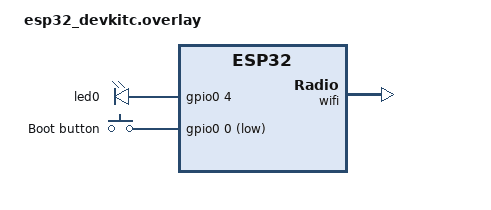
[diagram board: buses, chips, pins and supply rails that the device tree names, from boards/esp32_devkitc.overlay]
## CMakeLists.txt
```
cmake_minimum_required(VERSION 3.20.0)

find_package(Zephyr REQUIRED HINTS $ENV{ZEPHYR_BASE})
project(solution_http)

file(GLOB_RECURSE app_sources CONFIGURE_DEPENDS src/*.c)
target_sources(app PRIVATE ${app_sources})

set(gen_dir ${CMAKE_CURRENT_BINARY_DIR}/include/generated)
target_include_directories(app PRIVATE
    ${gen_dir}
    src
)

generate_inc_file_for_target(
    app
    web/index.html
    ${gen_dir}/index.html.inc
)

generate_inc_file_for_target(
    app
    web/style.css
    ${gen_dir}/style.css.inc
)

generate_inc_file_for_target(
    app
    web/app.js
    ${gen_dir}/app.js.inc
)

zephyr_linker_sources(SECTIONS src/web/sections-rom.ld)

zephyr_linker_section(
    NAME http_resource_desc_tv_scheduler
    KVMA RAM_REGION
    GROUP RODATA_REGION
)
```

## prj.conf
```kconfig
CONFIG_CRC=y
CONFIG_DNS_RESOLVER=y
CONFIG_EARLY_CONSOLE=y
CONFIG_EVENTFD=y
CONFIG_FLASH_MAP=y
CONFIG_FLASH=y
CONFIG_GPIO=y
CONFIG_HTTP_PARSER_URL=y
CONFIG_HTTP_PARSER=y
CONFIG_HTTP_SERVER_MAX_CLIENTS=10
CONFIG_HTTP_SERVER_RESOURCE_WILDCARD=y
CONFIG_HTTP_SERVER_STACK_SIZE=4096
CONFIG_HTTP_SERVER=y
CONFIG_IMG_MANAGER=y
CONFIG_INIT_STACKS=y
CONFIG_JSON_LIBRARY=y
CONFIG_LOG_BUFFER_SIZE=4096
CONFIG_LOG_MODE_DEFERRED=y
CONFIG_LOG=y
CONFIG_MCUMGR=y
CONFIG_NET_BUF_RX_COUNT=20
CONFIG_NET_BUF_RX_COUNT=32
CONFIG_NET_BUF_TX_COUNT=20
CONFIG_NET_BUF_TX_COUNT=32
CONFIG_NET_BUF=y
CONFIG_NET_CONFIG_AUTO_INIT=n
CONFIG_NET_CONNECTION_MANAGER=y
CONFIG_NET_DHCPV4_SERVER_LOG_LEVEL_DBG=y
CONFIG_NET_DHCPV4_SERVER=y
CONFIG_NET_DHCPV4=y
CONFIG_NET_IF_MAX_IPV4_COUNT=2
CONFIG_NET_IF_MAX_IPV6_COUNT=2
CONFIG_NET_IPV4=y
CONFIG_NET_IPV6=n
CONFIG_NET_L2_ETHERNET=y
CONFIG_NET_L2_WIFI_MGMT=y
CONFIG_NET_LOG=y
CONFIG_NET_MAX_CONN=16
CONFIG_NET_MAX_CONTEXTS=10
CONFIG_NET_MAX_CONTEXTS=16
CONFIG_NET_MAX_CONTEXTS=8
CONFIG_NET_MGMT_EVENT_INFO=y
CONFIG_NET_MGMT_EVENT_QUEUE_SIZE=10
CONFIG_NET_MGMT_EVENT_QUEUE_SIZE=16
CONFIG_NET_MGMT_EVENT_QUEUE_TIMEOUT=5000
CONFIG_NET_MGMT_EVENT_STACK_SIZE=4096
CONFIG_NET_MGMT_EVENT=y
CONFIG_NET_MGMT=y
CONFIG_NET_PKT_RX_COUNT=10
CONFIG_NET_PKT_RX_COUNT=16
CONFIG_NET_PKT_TX_COUNT=10
CONFIG_NET_PKT_TX_COUNT=16
CONFIG_NET_SOCKETS_SERVICE_STACK_SIZE=4096
CONFIG_NET_SOCKETS=y
CONFIG_NET_STATISTICS_PERIODIC_OUTPUT=n
CONFIG_NET_STATISTICS=y
CONFIG_NET_TCP_WORKQ_STACK_SIZE=2048
CONFIG_NET_TCP=y
CONFIG_NET_UDP=y
CONFIG_NETWORKING=y
CONFIG_NVS=y
CONFIG_POSIX_API=y
CONFIG_REBOOT=y
CONFIG_SETTINGS_NVS=y
CONFIG_SETTINGS=y
CONFIG_SNTP=y
CONFIG_STREAM_FLASH=y
CONFIG_SYSTEM_WORKQUEUE_STACK_SIZE=3072
CONFIG_SYSTEM_WORKQUEUE_STACK_SIZE=4096
CONFIG_TEST_RANDOM_GENERATOR=y
CONFIG_WIFI_LOG_LEVEL_DBG=y
CONFIG_WIFI_LOG_LEVEL_ERR=y
CONFIG_WIFI_NM=y
CONFIG_WIFI_USAGE_MODE_STA_AP=y
CONFIG_WIFI=y
CONFIG_ZCBOR=y
CONFIG_ZVFS_OPEN_MAX=32
CONFIG_ZVFS_POLL_MAX=32
```

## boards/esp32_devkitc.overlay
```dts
/ {
    aliases {
        tvrelay = &led0;

        /* Map the boot button to the standard 'sw0' alias */
        /* Most boards with a "BOOT" button use GPIO0 */
        /* boot-button = &gpio0; */
        /* sw0 = &boot_button_node; */
        /* Direct the standard alias to your board's built-in button_0 */
        sw0 = &button0;
    };

    leds {
        compatible = "gpio-leds";
        led0: user_led  {
            gpios = <&gpio0 4 GPIO_ACTIVE_HIGH>;
        };
    };

    gpio_keys {
        boot_button_node: button_0 {
            gpios = <&gpio0 0 (GPIO_ACTIVE_LOW | GPIO_PULL_UP)>;
            label = "Boot button";
        };
    };
};
&wifi {
	status = "okay";
};
```

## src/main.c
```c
#include "config.h"
#include "factory_mode_button.h"
#include "relay.h"
#include "scheduler.h"
#include "time_sync.h"
#include "web/http_server.h"
#include "wifi.h"
#include "wifi_manager.h"

#include <zephyr/device.h>
#include <zephyr/kernel.h>
#include <zephyr/logging/log.h>

LOG_MODULE_REGISTER(app_main, CONFIG_LOG_DEFAULT_LEVEL);

// --- Forward Declarations ---
static int init_core_peripherals(void);
static void run_provisioning_mode(void);
static void run_station_mode(void);

// ===================================================================================
// Main Application
// ===================================================================================

int main(void) {
  LOG_INF("\n=====================================");
  LOG_INF("      TV Scheduler Starting v1.0");
  LOG_INF("=====================================");

  if (init_core_peripherals() != 0) {
    LOG_ERR("FATAL: Core peripheral initialization failed. Halting.");
    return -1;
  }

  factory_reset_monitor_thread();

  if (wifi_manager_start() != 0) {
    LOG_ERR("FATAL: WiFi manager failed to start. Halting.");
    return -1;
  }

  // Based on the network mode, enter the appropriate main loop.
  if (wifi_manager_is_ap_mode()) {
    run_provisioning_mode();
  } else {
    run_station_mode();
  }

  // This part of the code should be unreachable
  LOG_ERR("FATAL: Main application loop exited unexpectedly. Halting.");
  return -1;
}

// ===================================================================================
// Helper Functions & Threads
// ===================================================================================

/**
 * @brief Initializes essential, non-network-related hardware.
 * @return 0 on success, negative error code on failure.
 */
static int init_core_peripherals(void) {
  LOG_INF("Initializing core peripherals...");
  config_load();

  if (relay_init() != 0) {
    LOG_ERR("Relay initialization failed.");
    return -EIO;
  }
  if (relay_set(false) != 0) {
    LOG_ERR("Failed to set initial relay state to ON.");
    return -EIO;
  }
  LOG_INF("Core peripherals initialized.");
  return 0;
}

/**
 * @brief The main application loop when in Access Point (AP) mode.
 * Serves the web page for configuration and does nothing else.
 */
static void run_provisioning_mode(void) {
  LOG_INF("Entering Provisioning (AP) Mode.");
  http_server_start_serving();

  while (1) {
    k_sleep(K_SECONDS(60));
    LOG_DBG("Provisioning mode heartbeat.");
  }
}

/**
 * @brief The main application loop when in Station (client) mode.
 * Synchronizes time and runs the scheduler.
 */
static void run_station_mode(void) {
  const app_config_t *cfg = config_get();

  LOG_INF("Entering Station (Client) Mode.");
  http_server_start_serving();

  // Robust Time Sync Loop: Keep trying until time is valid.
  while (!time_is_valid()) {
    LOG_WRN("System time is not yet valid. Attempting to synchronize...");
    if (time_sync() != 0) {
      LOG_ERR("Time synchronization failed. Retrying in 1 minute...");
      k_sleep(K_MINUTES(1));
    } else {
      LOG_INF("Time synchronization successful.");
    }
  }
  time_print(); // Print the valid time once.

  // Main Scheduler Loop
  LOG_INF("Starting main scheduler loop...");
  while (1) {
    bool should_block =
        !scheduler_evaluate_state(cfg->schedules, cfg->schedule_count);
    if (relay_set(!should_block) == 0) {
      LOG_INF("Relay state set to: %s", !should_block ? "BLOCKED" : "ALLOWED");
    } else {
      LOG_ERR("Failed to set relay state!");
    }
    scheduler_wait_for_next_evaluation(K_MINUTES(1));
    // k_sleep(K_MINUTES(1));
  }
}
```

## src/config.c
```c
#include "config.h"
#include <errno.h>
#include <string.h>
#include <zephyr/kernel.h>
#include <zephyr/logging/log.h>
#include <zephyr/settings/settings.h>

LOG_MODULE_REGISTER(config_storage, CONFIG_LOG_DEFAULT_LEVEL);

// The single, global instance of our application's configuration.
static app_config_t config;

// Guard to ensure settings subsystem is initialized only once.
static bool is_initialized = false;

// --- Settings Subsystem Handlers ---

static int app_settings_set(const char *name, size_t len,
                            settings_read_cb read_cb, void *cb_arg) {
  const char *next;
  if (settings_name_steq(name, "config", &next) && !next) {
    if (len != sizeof(app_config_t)) {
      LOG_ERR(
          "Config size mismatch! Flash: %d, RAM: %d. Ignoring stored settings.",
          (int)len, sizeof(app_config_t));
      return -EINVAL;
    }

    app_config_t loaded_config;
    int rc = read_cb(cb_arg, &loaded_config, sizeof(loaded_config));
    if (rc < 0) {
      LOG_ERR("Failed to read config from flash (err: %d)", rc);
      return rc;
    }

    // CRITICAL: Check version of loaded config against firmware version.
    if (loaded_config.version != CONFIG_VERSION) {
      LOG_WRN("Config version mismatch! Flash: %u, FW: %u. Applying factory "
              "defaults.",
              loaded_config.version, CONFIG_VERSION);
      return -EINVAL; // Mismatch triggers a factory reset in config_load.
    }

    // Versions match, apply the loaded configuration.
    memcpy(&config, &loaded_config, sizeof(app_config_t));
    LOG_INF("Configuration loaded successfully from Flash (version %u).",
            config.version);
    return 0;
  }
  return -ENOENT;
}

static int app_settings_export(int (*storage_func)(const char *name,
                                                   const void *value,
                                                   size_t val_len)) {
  return storage_func("app/config", &config, sizeof(app_config_t));
}

static struct settings_handler app_conf_handler = {
    .name = "app",
    .h_set = app_settings_set,
    .h_export = app_settings_export,
};

// --- Public API ---

void config_factory_reset(void) {
  LOG_WRN("Performing factory reset. All settings will be lost.");
  memset(&config, 0, sizeof(config));
  config.version = CONFIG_VERSION;
  strncpy(config.name, "My New IoT Device", sizeof(config.name) - 1);
  strncpy(config.timezone, "IST-5:30", sizeof(config.timezone) - 1);
  config.max_on_time_minutes = 0;
  config.schedule_count = 1;
  schedule_t *schedule = &config.schedules[0];
  schedule->enabled = true;
  schedule->day_mask = 62; // Mon - Fri
  schedule->start_hour = 9;
  schedule->start_minute = 0;
  schedule->end_hour = 17;
  schedule->end_minute = 0;
}

void config_load(void) {
  if (!is_initialized) {
    int rc = settings_subsys_init();
    if (rc != 0) {
      LOG_ERR("Settings subsystem initialization failed (err: %d). Loading "
              "defaults.",
              rc);
      config_factory_reset();
      return;
    }
    rc = settings_register(&app_conf_handler);
    if (rc != 0) {
      LOG_ERR("Failed to register settings handler (err: %d).", rc);
    }
    is_initialized = true;
  }

  // Attempt to load settings from persistent storage.
  int rc = settings_load();
  if (rc != 0) {
    LOG_WRN("No saved config found, or load failed/rejected (err: %d). Loading "
            "defaults.",
            rc);
    config_factory_reset();
    // Save the fresh factory defaults to flash immediately.
    config_save();
  }
}

int config_save(void) {
  LOG_INF("Attempting to save configuration to flash...");
  config_dump(); // Log what we're about to save.

  int rc = settings_save();
  if (rc != 0) {
    LOG_ERR("Failed to save configuration to Flash (err: %d)", rc);
  } else {
    LOG_INF("Configuration successfully saved to Flash.");
  }
  return rc;
}

// --- Debugging & Getters ---

static void print_byte_as_binary(uint8_t byte) {
  LOG_MODULE_DECLARE(config_storage,
                     CONFIG_LOG_DEFAULT_LEVEL); // Ensure LOG_* can be used here
  char bin_str[11] = "0b";                      // 0b + 8 bits + null terminator
  for (int i = 7; i >= 0; i--) {
    bin_str[9 - i] = ((byte >> i) & 1) ? '1' : '0';
  }
  printk("%s",
         bin_str); // Use printk for inline printing without extra log headers
}

void config_dump(void) {
  LOG_INF("--- CONFIGURATION DUMP ---");
  LOG_INF("Version: %u", config.version);
  LOG_INF("-- Device Settings --");
  LOG_INF("Name: '%s'", config.name);
  LOG_INF("WiFi SSID: '%s'", config.wifi_ssid);
  // SECURITY: Do not log the cleartext password.
  LOG_INF("WiFi Password: '[****]'");
  LOG_INF("Timezone: '%s'", config.timezone);
  LOG_INF("Max On-Time (minutes): %u", config.max_on_time_minutes);
  LOG_INF("-- Schedules (%u) --", config.schedule_count);

  if (config.schedule_count == 0) {
    LOG_INF("No schedules defined.");
  } else {
    for (int i = 0; i < config.schedule_count; i++) {
      const schedule_t *s = &config.schedules[i];
      char buf[128];
      int pos = 0;
      pos += snprintf(buf + pos, sizeof(buf) - pos, "--- Schedule %d ---\n",
                      i + 1);
      pos += snprintf(buf + pos, sizeof(buf) - pos,
                      "  Enabled: %s | Day Mask: %u (",
                      s->enabled ? "true" : "false", s->day_mask);
      printk("%s", buf); // Print buffer before binary part
      print_byte_as_binary(s->day_mask);
      printk(") | Time: %02u:%02u - %02u:%02u\n", s->start_hour,
             s->start_minute, s->end_hour, s->end_minute);
    }
  }
  LOG_INF("--- END OF DUMP ---");
}

const app_config_t *config_get(void) { return &config; }

app_config_t *config_get_editable(void) { return &config; }
```

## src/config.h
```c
#ifndef CONFIG_H
#define CONFIG_H

#include <stdbool.h> // Include for bool type
#include <stdint.h>

#define CONFIG_VERSION 1

// Define maximum lengths for string fields
#define DEVICE_NAME_MAX_LEN 32
#define WIFI_SSID_MAX_LEN 32
#define WIFI_PASSWORD_MAX_LEN 64
#define TIMEZONE_MAX_LEN 32
#define MAX_SCHEDULES 8

/**
 * @brief Defines a single schedule entry.
 * Uses a bitmask for days of the week.
 */
typedef struct {
  bool enabled;
  uint8_t day_mask; // Bit 0:Sun, 1:Mon, ..., 6:Sat
  uint8_t start_hour;
  uint8_t start_minute;
  uint8_t end_hour;
  uint8_t end_minute;
} schedule_t;

/**
 * @brief Defines the entire device configuration structure.
 * This is what will be saved to and loaded from persistent storage.
 */
typedef struct {
  uint32_t version;

  // Device Settings
  char name[DEVICE_NAME_MAX_LEN];
  char wifi_ssid[WIFI_SSID_MAX_LEN];
  char wifi_password[WIFI_PASSWORD_MAX_LEN];
  char timezone[TIMEZONE_MAX_LEN];
  uint16_t max_on_time_minutes;

  // Schedule Settings
  uint8_t schedule_count;
  schedule_t schedules[MAX_SCHEDULES];
} app_config_t;

/**
 * @brief Loads the configuration from persistent storage (or sets defaults).
 * This should be called once at startup.
 */
void config_load(void);

/**
 * @brief Saves the current configuration to persistent storage.
 * @return 0 on success, or a negative error code on failure.
 */
int config_save(void);

/**
 * @brief Prints the entire current configuration to the console for debugging.
 */
void config_dump(void);

/**
 * @brief Resets the configuration to factory defaults.
 */
void config_factory_reset(void);

/**
 * @brief Gets a read-only pointer to the current configuration.
 * Use this for functions that only need to read settings.
 * @return const app_config_t* A pointer to the global config struct.
 */
const app_config_t *config_get(void);

/**
 * @brief Gets a mutable (writeable) pointer to the current configuration.
 * Use this for functions that need to modify settings before calling
 * config_save().
 * @return app_config_t* A pointer to the global config struct.
 */
app_config_t *config_get_editable(void);

#endif /* CONFIG_H */
```

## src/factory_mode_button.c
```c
#include "factory_mode_button.h"

LOG_MODULE_REGISTER(factory_mode_button, CONFIG_LOG_DEFAULT_LEVEL);

static const struct gpio_dt_spec button =
    GPIO_DT_SPEC_GET_OR(SW0_NODE, gpios, {0});
K_THREAD_STACK_DEFINE(button_stack_area, 1024);
struct k_thread button_thread_data;

void factory_reset_monitor_thread(void) {
  if (button.port) {
    k_thread_create(&button_thread_data, button_stack_area,
                    K_THREAD_STACK_SIZEOF(button_stack_area),
                    button_monitor_thread_entry, NULL, NULL, NULL, 5, 0,
                    K_NO_WAIT);
    LOG_INF("Button monitor thread started.");
  } else {
    LOG_WRN("No boot button alias found; long-press reset is disabled.");
  }
}

/**

 * @brief This thread runs in the background to detect a long press on the boot
 * button.
 */
void button_monitor_thread_entry(void *p1, void *p2, void *p3) {
  if (!device_is_ready(button.port)) {
    LOG_ERR("Button device is not ready.");
    return;
  }
  if (gpio_pin_configure_dt(&button, GPIO_INPUT) != 0) {
    LOG_ERR("Failed to configure button GPIO.");
    return;
  }

  LOG_INF("Button monitor active. Hold button for %d seconds to enter AP mode.",
          LONG_PRESS_DURATION_MS / 1000);
  int64_t press_start_time = 0;
  bool is_pressed = false;

  while (1) {
    if (gpio_pin_get_dt(&button) > 0) { // Button is pressed
      if (!is_pressed) {
        press_start_time = k_uptime_get();
        is_pressed = true;
      } else {
        int64_t elapsed = k_uptime_get() - press_start_time;
        if (elapsed >= LONG_PRESS_DURATION_MS) {
          LOG_WRN("Long press detected! Clearing WiFi config and rebooting...");
          app_config_t *cfg = config_get_editable();
          memset(cfg->wifi_ssid, 0, sizeof(cfg->wifi_ssid));
          memset(cfg->wifi_password, 0, sizeof(cfg->wifi_password));
          config_save();
          k_sleep(K_MSEC(200));
          sys_reboot(SYS_REBOOT_COLD);
        }
      }
    } else { // Button is not pressed
      is_pressed = false;
    }
    k_msleep(100);
  }
}
```

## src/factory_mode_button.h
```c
#ifndef FACTORY_MODE_BUTTON_H
#define FACTORY_MODE_BUTTON_H

#include <zephyr/device.h>
#include <zephyr/drivers/gpio.h>
#include <zephyr/kernel.h>
#include <zephyr/logging/log.h>
#include <zephyr/sys/reboot.h>

#include "config.h"
// --- Button Configuration & Thread Definition ---
#define LONG_PRESS_DURATION_MS 5000
#define SW0_NODE DT_ALIAS(sw0)

void factory_reset_monitor_thread(void);
void button_monitor_thread_entry(void *p1, void *p2, void *p3);

#endif
```

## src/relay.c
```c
#include "relay.h"
#include <zephyr/device.h>
#include <zephyr/drivers/gpio.h>
#include <zephyr/kernel.h>
#include <zephyr/logging/log.h> // Include Zephyr's logging header

// Register this file as a log module
LOG_MODULE_REGISTER(relay_driver, CONFIG_LOG_DEFAULT_LEVEL);

// --- Hardware and State Definition ---

// Get the relay specification from the devicetree
static const struct gpio_dt_spec relay =
    GPIO_DT_SPEC_GET(DT_ALIAS(tvrelay), gpios);

// The number of times to retry a GPIO set operation if it fails
#define RELAY_SET_RETRIES 3

// The internal state of the relay. This is the "source of truth" for the
// software.
static bool relay_state;

// --- Driver Implementation ---

/**
 * @brief Initializes the relay GPIO pin.
 * This is the most critical function. If it fails, the device cannot operate.
 */
int relay_init(void) {
  if (!gpio_is_ready_dt(&relay)) {
    // This is a fatal, non-recoverable error. The DT is misconfigured or the
    // hardware is missing.
    LOG_ERR("Relay GPIO device not ready: %s", relay.port->name);
    return -ENODEV;
  }

  int ret = gpio_pin_configure_dt(&relay, GPIO_OUTPUT_INACTIVE);
  if (ret != 0) {
    LOG_ERR("Failed to configure relay GPIO pin %d (error %d)", relay.pin, ret);
    return ret;
  }

  // Successfully configured. The relay is physically OFF.
  relay_state = false;
  LOG_INF("Relay initialized successfully, state: OFF");
  return 0;
}

/**
 * @brief Turns the relay ON with retry logic.
 * This is now an internal helper function.
 */
static int relay_on_internal(void) {
  int ret = -1;
  for (int i = 0; i < RELAY_SET_RETRIES; i++) {
    ret = gpio_pin_set_dt(&relay, 1);
    if (ret == 0) {
      // SUCCESS: Update state and exit loop
      relay_state = true;
      return 0;
    }
    LOG_WRN("Failed to set relay ON on attempt %d/%d (error %d). Retrying...",
            i + 1, RELAY_SET_RETRIES, ret);
    k_msleep(10); // Small delay before retrying
  }

  // If we exit the loop, all retries have failed.
  LOG_ERR("FATAL: Failed to set relay ON after %d attempts.",
          RELAY_SET_RETRIES);
  relay_state = false; // Failsafe: assume it's off if we can't control it.
  return ret;
}

/**
 * @brief Turns the relay OFF with retry logic.
 * This is now an internal helper function.
 */
static int relay_off_internal(void) {
  int ret = -1;
  for (int i = 0; i < RELAY_SET_RETRIES; i++) {
    ret = gpio_pin_set_dt(&relay, 0);
    if (ret == 0) {
      // SUCCESS: Update state and exit loop
      relay_state = false;
      return 0;
    }
    LOG_WRN("Failed to set relay OFF on attempt %d/%d (error %d). Retrying...",
            i + 1, RELAY_SET_RETRIES, ret);
    k_msleep(10); // Small delay before retrying
  }

  // If we exit the loop, all retries have failed.
  LOG_ERR("FATAL: Failed to set relay OFF after %d attempts.",
          RELAY_SET_RETRIES);
  // The actual state is unknown, but we must assume the worst-case (it may be
  // stuck on). The internal state is now out of sync with hardware.
  return ret;
}

/**
 * @brief Sets the relay to a desired state (ON or OFF).
 * This is the primary public function to control the relay.
 */
int relay_set(bool on) {
  // State-change guard: only perform an action if the requested state is
  // different from the current state.
  if (on == relay_state) {
    return 0; // Already in the desired state, do nothing.
  }

  LOG_INF("Relay state changing to: %s", on ? "ON" : "OFF");

  if (on) {
    return relay_on_internal();
  } else {
    return relay_off_internal();
  }
}

int relay_off() { return relay_set(false); }

int relay_on() { return relay_set(true); }

/**
 * @brief Returns the last known successful state of the relay.
 */
bool relay_is_on(void) { return relay_state; }
```

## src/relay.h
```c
#ifndef RELAY_H
#define RELAY_H

#include <stdbool.h>

/**
 * @brief Initialize the relay GPIO.
 *
 * @return 0 on success, negative error code otherwise.
 */
int relay_init(void);

/**
 * @brief Turn the relay ON.
 */
int relay_on(void);

/**
 * @brief Turn the relay OFF.
 */
int relay_off(void);

/**
 * @brief Set relay state.
 *
 * @param on true = ON, false = OFF
 */
int relay_set(bool on);

/**
 * @brief Get current relay state.
 *
 * @return true if relay is ON.
 */
bool relay_is_on(void);

#endif /* RELAY_H */
```

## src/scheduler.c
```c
#include "scheduler.h"
#include "time_sync.h" // Needed for the time_is_valid() check
#include <stdbool.h>
#include <time.h>
#include <zephyr/kernel.h>
#include <zephyr/logging/log.h>

LOG_MODULE_REGISTER(scheduler, CONFIG_LOG_DEFAULT_LEVEL);

// --- CENTRALIZED OPERATIONAL STATE VARIABLES ---
static bool override_active = false;
static bool override_state =
    false; // true = Block (Relay ON), false = Allow (Relay OFF)
static int64_t temp_allow_expiry_ms = 0; // Expiry uptime stamp in milliseconds

// Define a kernel semaphore to synchronize immediate web/button updates with
// the scheduler thread
static K_SEM_DEFINE(scheduler_sem, 0, 1);

/*------------------------------------------------------------------
 * Helpers
 *-----------------------------------------------------------------*/

/**
 * @brief Checks if a schedule is active for a given day of the week using a
 * bitmask.
 * @param schedule The schedule to check.
 * @param weekday The day of the week (0=Sun, 1=Mon, ..., 6=Sat), matching
 * tm_wday.
 * @return True if the day's corresponding bit is set in the mask, false
 * otherwise.
 */
static bool is_day_enabled(const schedule_t *schedule, int weekday) {
  if (weekday < 0 || weekday > 6) {
    LOG_ERR("Invalid weekday index received: %d", weekday);
    return false;
  }
  return (schedule->day_mask & (1 << weekday)) != 0;
}

/**
 * @brief Converts an hour and minute into a total number of minutes since
 * midnight.
 */
static int minutes_since_midnight(int hour, int minute) {
  return (hour * 60) + minute;
}

/*------------------------------------------------------------------
 * Core Scheduler Logic
 *-----------------------------------------------------------------*/

/**
 * @brief Determines if the device should be blocked (i.e., ON) based on a
 * single schedule.
 */
bool scheduler_should_block(const schedule_t *schedule) {
  if (schedule == NULL) {
    return false;
  }
  if (!schedule->enabled) {
    LOG_DBG("Schedule is disabled.");
    return false;
  }

  // CRITICAL: Do not run standard scheduling calculations if time is invalid
  if (!time_is_valid()) {
    LOG_WRN("Cannot evaluate schedule, system time is not valid/synchronized.");
    return false;
  }

  // Get current time information
  struct timespec ts;
  struct tm tm;
  clock_gettime(CLOCK_REALTIME, &ts);
  localtime_r(&ts.tv_sec, &tm);

  // Check if today is an active day for this schedule
  if (!is_day_enabled(schedule, tm.tm_wday)) {
    LOG_DBG("Day %d is not enabled for this schedule (mask: %u).", tm.tm_wday,
            schedule->day_mask);
    return false;
  }

  // Check if current time falls within the scheduled block (with overnight
  // support)
  const int current_minutes = minutes_since_midnight(tm.tm_hour, tm.tm_min);
  const int start_minutes =
      minutes_since_midnight(schedule->start_hour, schedule->start_minute);
  const int end_minutes =
      minutes_since_midnight(schedule->end_hour, schedule->end_minute);

  bool is_active;
  if (start_minutes <= end_minutes) {
    // --- Normal Case: Schedule does NOT cross midnight (e.g., 09:00 - 17:00)
    // ---
    is_active =
        (current_minutes >= start_minutes) && (current_minutes < end_minutes);
    LOG_DBG("Normal schedule check: start=%d, end=%d, current=%d. Active: %s",
            start_minutes, end_minutes, current_minutes,
            is_active ? "yes" : "no");
  } else {
    // --- Overnight Case: Schedule CROSSES midnight (e.g., 22:00 - 02:00) ---
    is_active =
        (current_minutes >= start_minutes) || (current_minutes < end_minutes);
    LOG_DBG(
        "Overnight schedule check: start=%d, end=%d, current=%d. Active: %s",
        start_minutes, end_minutes, current_minutes, is_active ? "yes" : "no");
  }

  return is_active;
}

/**
 * @brief Checks if any schedule in an array requires the device to be blocked.
 */
bool scheduler_should_block_any(const schedule_t *schedules, size_t count) {
  if (schedules == NULL || count == 0) {
    return false;
  }

  LOG_DBG("Evaluating %u schedule(s)...", (uint32_t)count);
  for (size_t i = 0; i < count; i++) {
    if (scheduler_should_block(&schedules[i])) {
      LOG_INF("Schedule %u is active. Device will be blocked.",
              (uint32_t)i + 1);
      return true; // If any schedule matches, we block.
    }
  }
  LOG_DBG("No active schedules found.");
  return false;
}

// ===================================================================================
// PUBLIC API FOR MANUAL OVERRIDES & TIME COUNTDOWNS
// ===================================================================================

/**
 * @brief Checks if a manual or temporary override is currently active.
 * @param state Pointer to write the active override state to (true = Block,
 * false = Allow).
 * @return true if an override is active, false if the system should follow
 * standard schedules.
 */
bool scheduler_get_override_state(bool *state) {
  if (temp_allow_expiry_ms > 0) {
    if (k_uptime_get() < temp_allow_expiry_ms) {
      *state = false; // Forced ALLOW state (Relay OFF / appliance running)
      return true;
    } else {
      // Temporary allow period has expired
      LOG_INF("Temporary allow countdown has expired. Returning control to "
              "schedule plans.");
      temp_allow_expiry_ms = 0;
      override_active = false;
    }
  }

  if (override_active) {
    *state = override_state;
    return true;
  }

  return false;
}

/**
 * @brief Sets a persistent manual override state.
 * @param block_state true to force block (Appliance OFF / Relay ON), false to
 * force allow (Appliance ON / Relay OFF).
 */
void scheduler_set_manual_override(bool block_state) {
  override_active = true;
  override_state = block_state;
  temp_allow_expiry_ms = 0; // Clear any active countdown timers

  LOG_INF("Manual override set to %s. Triggering immediate thread evaluation.",
          block_state ? "FORCED BLOCK" : "FORCED ALLOW");
  scheduler_trigger_evaluation();
}

/**
 * @brief Activates a temporary allow countdown.
 * @param duration_minutes Time duration in minutes to bypass schedules.
 */
void scheduler_set_temporary_allow(uint32_t duration_minutes) {
  temp_allow_expiry_ms =
      k_uptime_get() + ((int64_t)duration_minutes * 60 * 1000);
  override_active = true;
  override_state = false; // false = Allow (Relay OFF)

  LOG_INF("Temporary allow countdown activated for %u minute(s). Triggering "
          "evaluation.",
          duration_minutes);
  scheduler_trigger_evaluation();
}

/**
 * @brief Clears all active overrides and returns control to standard schedules.
 */
void scheduler_clear_override(void) {
  override_active = false;
  temp_allow_expiry_ms = 0;

  LOG_INF("Manual overrides cleared. System returning to automatic schedule.");
  scheduler_trigger_evaluation();
}

// ===================================================================================
// CENTRAL DECISION ENGINE (UNIFIED OVERRIDE & SCHEDULER ORCHESTRATION)
// ===================================================================================

/**
 * @brief Centralized state coordinator for the appliance.
 *        Resolves all competing variables (manual commands, timers, and offline
 * status) in one place.
 *
 * Evaluation Sequence (Strict Priority):
 * 1. Active Manual Overrides: Direct ON/OFF commands and active temporary allow
 * countdowns.
 * 2. Time Validity: If offline/unsynced, defaults to a safe ALLOWED state.
 * 3. Scheduled blocks: Evaluated only if there are no active overrides and time
 * is valid.
 *
 * @param schedules Pointer to the array of schedule definitions.
 * @param count Number of schedules in the array.
 * @return true if the device should block (Relay ON), false if allowed (Relay
 * OFF).
 */
bool scheduler_evaluate_state(const schedule_t *schedules, size_t count) {
  bool override_val = false;

  // 1. Highest Priority: Manual/Timed Overrides (Checked locally and natively!)
  if (scheduler_get_override_state(&override_val)) {
    LOG_DBG("Decision: Override active. Forcing block state to: %s",
            override_val ? "BLOCKED (Relay ON)" : "ALLOWED (Relay OFF)");
    return override_val;
  }

  // 2. Medium Priority: Network Time Sync Safety Gate
  if (!time_is_valid()) {
    LOG_WRN("Decision: System time invalid/unsynced. Defaulting to safe "
            "ALLOWED (OFF) state.");
    return false;
  }

  // 3. Normal Priority: Standard Scheduled Rules
  bool scheduled_block = scheduler_should_block_any(schedules, count);
  LOG_DBG("Decision: Following scheduled plans. Block state: %s",
          scheduled_block ? "BLOCKED (Relay ON)" : "ALLOWED (Relay OFF)");
  return scheduled_block;
}

/**
 * @brief Signals the central coordinator thread that a configuration state has
 * changed. Wakes the background loop up immediately to apply modifications.
 */
void scheduler_trigger_evaluation(void) { k_sem_give(&scheduler_sem); }

/**
 * @brief Thread sleep handler that waits for either the next periodic
 * evaluation window or an immediate state-change wake-up signal.
 */
void scheduler_wait_for_next_evaluation(k_timeout_t max_delay_seconds) {
  k_sem_take(&scheduler_sem, (max_delay_seconds));
}
```

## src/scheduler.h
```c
#ifndef SCHEDULER_H
#define SCHEDULER_H

#include "config.h"
#include <stdbool.h>
#include <stddef.h>
#include <stdint.h>
#include <zephyr/sys/clock.h>

/*
 * Returns true if the current time falls inside this schedule.
 */
bool scheduler_should_block(const schedule_t *schedule);

/*
 * Returns true if ANY enabled schedule matches.
 */
bool scheduler_should_block_any(const schedule_t *schedules, size_t count);

void scheduler_set_manual_override(bool block_state);
void scheduler_set_temporary_allow(uint32_t duration_minutes);
void scheduler_clear_override(void);
void scheduler_trigger_evaluation(void);
bool scheduler_evaluate_state(const schedule_t *schedules, size_t count);
void scheduler_wait_for_next_evaluation(k_timeout_t max_delay_seconds);

#endif
```

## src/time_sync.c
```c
#include "time_sync.h"
#include "config.h"
#include <errno.h>
#include <stdlib.h>
#include <time.h>
#include <zephyr/kernel.h>
#include <zephyr/logging/log.h> // Include Zephyr's logging header
#include <zephyr/net/sntp.h>

// Register this file as a log module
LOG_MODULE_REGISTER(time_sync_module, CONFIG_LOG_DEFAULT_LEVEL);

// --- Configuration ---
#define SNTP_TIMEOUT_MS 5000  // Timeout for a single SNTP request
#define SYNC_RETRIES 3        // Number of retry attempts per server
#define RETRY_BACKOFF_MS 2000 // Time to wait between retries

// Define a list of NTP servers for fallback capability
static const char *sntp_servers[] = {
    "time.google.com", // Primary
    "pool.ntp.org",    // Secondary
};

int update_system_timezone(const char *tz_string) {
  // Set environmental timezone variable (e.g. "EST5EDT" or "IST-5:30")
  setenv("TZ", tz_string, 1);

  // Apply changes to POSIX time libraries
  tzset();

  LOG_INF("System timezone updated to: %s", tz_string);
  return 0;
}

// --- Public API ---

/**
 * @brief Attempts to synchronize the system time using SNTP with retries and
 * fallbacks.
 * @return 0 on success, or a negative error code if all attempts fail.
 */
int time_sync(void) {
  int ret = -1;

  // Loop through all configured NTP servers
  for (int i = 0; i < ARRAY_SIZE(sntp_servers); i++) {
    const char *server = sntp_servers[i];
    LOG_INF("Attempting time synchronization with %s...", server);

    // Retry the synchronization several times for the current server
    for (int j = 0; j < SYNC_RETRIES; j++) {
      struct sntp_time ts;
      ret = sntp_simple(server, SNTP_TIMEOUT_MS, &ts);

      if (ret == 0) {
        // SUCCESS: Time was received from the SNTP server
        struct timespec tp = {
            .tv_sec = ts.seconds,
            .tv_nsec = ((uint64_t)ts.fraction * 1000000000ULL) >> 32,
        };

        ret = clock_settime(CLOCK_REALTIME, &tp);
        if (ret != 0) {
          LOG_ERR("Failed to set system clock (error %d, errno %d)", ret,
                  errno);
          return ret; // This is a critical system error, no point in retrying
        }

        const app_config_t *cfg = config_get();

        update_system_timezone(cfg->timezone);

        LOG_INF("Time synchronized successfully via %s", server);
        return 0; // Exit function on first success
      }

      LOG_WRN("SNTP failed on attempt %d/%d with %s (error %d). Retrying in "
              "%dms...",
              j + 1, SYNC_RETRIES, server, ret, RETRY_BACKOFF_MS);
      k_msleep(RETRY_BACKOFF_MS);
    }
  }

  // If we exit the loops, all attempts on all servers have failed.
  LOG_ERR("All SNTP attempts failed. Unable to synchronize time.");
  return ret; // Return the last error code from sntp_simple
}

/**
 * @brief Checks if the system time appears to be valid (i.e., has been set).
 */
bool time_is_valid(void) {
  struct timespec ts;
  clock_gettime(CLOCK_REALTIME, &ts);

  // A simple check to see if the time is after ~Nov 2023.
  // This indicates the clock has been set from its Unix epoch default of 0.
  return ts.tv_sec > 1700000000;
}

/**
 * @brief Prints the current system time to the console.
 */
void time_print(void) {
  struct timespec ts;
  struct tm tm;
  char buffer[64];

  clock_gettime(CLOCK_REALTIME, &ts);
  time_t now = ts.tv_sec;
  localtime_r(&now, &tm); // Use re-entrant version for thread safety

  strftime(buffer, sizeof(buffer), "%A %Y-%m-%d %H:%M:%S %Z", &tm);
  LOG_INF("Current time: %s", buffer);
}
```

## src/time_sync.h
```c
#ifndef TIME_SYNC_H
#define TIME_SYNC_H

#include <stdbool.h>

/**
 * Synchronize system time using SNTP.
 *
 * Returns 0 on success.
 */
int time_sync(void);

/**
 * Print current local time.
 */
void time_print(void);

/**
 * Returns true if system time looks valid.
 */
bool time_is_valid(void);

#endif
```

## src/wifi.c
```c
#include "wifi.h"

#include <errno.h>
#include <string.h>

#include <zephyr/kernel.h>
#include <zephyr/logging/log.h>
#include <zephyr/net/net_if.h>
#include <zephyr/net/wifi_mgmt.h>

LOG_MODULE_REGISTER(wifi_driver, CONFIG_LOG_DEFAULT_LEVEL);

#define WIFI_CONNECT_TIMEOUT_S 30
#define IP_ADDR_OBTAIN_TIMEOUT_S 30

static struct net_mgmt_event_callback wifi_cb;
static struct net_mgmt_event_callback ipv4_cb;

static K_SEM_DEFINE(sem_wifi_connected, 0, 1);
static K_SEM_DEFINE(sem_ipv4_obtained, 0, 1);

static bool is_connected;
static wifi_disconnect_callback_t disconnect_callback;

/* -------------------------------------------------------------------------- */
/* Event handlers                                                             */
/* -------------------------------------------------------------------------- */

static void on_wifi_mgmt_event(struct net_mgmt_event_callback *cb,
                               uint64_t mgmt_event, struct net_if *iface) {
  const struct wifi_status *status = (const struct wifi_status *)cb->info;

  ARG_UNUSED(iface);

  switch (mgmt_event) {
  case NET_EVENT_WIFI_CONNECT_RESULT:
    if (status->status == 0) {
      LOG_INF("Wi-Fi connected successfully!");
      is_connected = true;
    } else {
      LOG_ERR("Wi-Fi connection failed with status: %d", status->status);
      is_connected = false;
    }

    k_sem_give(&sem_wifi_connected);
    break;

  case NET_EVENT_WIFI_DISCONNECT_RESULT:
    LOG_INF("Wi-Fi disconnected.");

    is_connected = false;

    /*
     * These semaphores belong to the current connection.
     * A subsequent connection must wait for fresh events.
     */
    k_sem_reset(&sem_wifi_connected);
    k_sem_reset(&sem_ipv4_obtained);

    /*
     * Do not reconnect here.
     *
     * The callback only notifies the owner of the Wi-Fi policy.
     */
    if (disconnect_callback != NULL) {
      disconnect_callback();
    }

    break;

  default:
    break;
  }
}

static void on_ipv4_mgmt_event(struct net_mgmt_event_callback *cb,
                               uint64_t mgmt_event, struct net_if *iface) {
  ARG_UNUSED(cb);

  if (mgmt_event != NET_EVENT_IPV4_ADDR_ADD) {
    return;
  }

  for (int i = 0; i < NET_IF_MAX_IPV4_ADDR; i++) {
    struct net_if_addr *ifaddr = &iface->config.ip.ipv4->unicast[i].ipv4;

    if (ifaddr->is_used && ifaddr->addr_type == NET_ADDR_DHCP) {

      char ip_buf[NET_IPV4_ADDR_LEN];

      if (net_addr_ntop(AF_INET, &ifaddr->address.in_addr, ip_buf,
                        sizeof(ip_buf))) {
        LOG_INF("IPv4 address obtained via DHCP: %s", ip_buf);

        k_sem_give(&sem_ipv4_obtained);
        return;
      }
    }
  }
}

/* -------------------------------------------------------------------------- */
/* Public API                                                                 */
/* -------------------------------------------------------------------------- */

void wifi_init(void) {
  net_mgmt_init_event_callback(&wifi_cb, on_wifi_mgmt_event,
                               NET_EVENT_WIFI_CONNECT_RESULT |
                                   NET_EVENT_WIFI_DISCONNECT_RESULT);

  net_mgmt_init_event_callback(&ipv4_cb, on_ipv4_mgmt_event,
                               NET_EVENT_IPV4_ADDR_ADD);

  net_mgmt_add_event_callback(&wifi_cb);
  net_mgmt_add_event_callback(&ipv4_cb);
}

void wifi_set_disconnect_callback(wifi_disconnect_callback_t callback) {
  disconnect_callback = callback;
}

bool wifi_is_connected(void) { return is_connected; }

int wifi_connect(const char *ssid, const char *psk) {
  /*
   * There are two Wi-Fi interfaces in this application:
   * STA and AP. Do not rely on net_if_get_default().
   */
  struct net_if *iface = net_if_get_wifi_sta();

  if (iface == NULL) {
    LOG_ERR("Could not get Wi-Fi STA interface.");
    return -ENODEV;
  }

  struct wifi_connect_req_params params = {
      .ssid = (const uint8_t *)ssid,
      .ssid_length = strlen(ssid),
      .psk = (const uint8_t *)psk,
      .psk_length = strlen(psk),
      .security = (psk != NULL && params.psk_length > 0)
                      ? WIFI_SECURITY_TYPE_PSK
                      : WIFI_SECURITY_TYPE_NONE,
      .channel = WIFI_CHANNEL_ANY,
  };

  k_sem_reset(&sem_wifi_connected);
  is_connected = false;

  LOG_INF("Attempting to connect to SSID: %s", ssid);

  int ret = net_mgmt(NET_REQUEST_WIFI_CONNECT, iface, &params, sizeof(params));

  if (ret != 0) {
    LOG_ERR("Wi-Fi connection request failed with error: %d", ret);
    return ret;
  }

  if (k_sem_take(&sem_wifi_connected, K_SECONDS(WIFI_CONNECT_TIMEOUT_S)) != 0) {

    LOG_ERR("Wi-Fi connection timed out after %u seconds.",
            WIFI_CONNECT_TIMEOUT_S);

    /*
     * This generates NET_EVENT_WIFI_DISCONNECT_RESULT.
     *
     * wifi_manager ignores that event while a connection
     * attempt is already in progress.
     */
    (void)net_mgmt(NET_REQUEST_WIFI_DISCONNECT, iface, NULL, 0);

    return -ETIMEDOUT;
  }

  return is_connected ? 0 : -EIO;
}

int wifi_wait_for_ip_addr(void) {
  if (k_sem_take(&sem_ipv4_obtained, K_SECONDS(IP_ADDR_OBTAIN_TIMEOUT_S)) !=
      0) {

    LOG_ERR("DHCP (IPv4 address) lease timed out after %u seconds.",
            IP_ADDR_OBTAIN_TIMEOUT_S);

    return -ETIMEDOUT;
  }

  return 0;
}

int wifi_disconnect(void) {
  struct net_if *iface = net_if_get_wifi_sta();

  if (iface == NULL) {
    return -ENODEV;
  }

  int ret = net_mgmt(NET_REQUEST_WIFI_DISCONNECT, iface, NULL, 0);

  if (ret != 0) {
    LOG_ERR("Wi-Fi disconnection request failed with error: %d", ret);
  }

  return ret;
}
```

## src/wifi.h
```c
#ifndef WIFI_H_
#define WIFI_H_

#include <stdbool.h>

typedef void (*wifi_disconnect_callback_t)(void);
void wifi_set_disconnect_callback(wifi_disconnect_callback_t callback);
// Function prototypes
void wifi_init(void);
int wifi_connect(const char *ssid, const char *psk);
int wifi_wait_for_ip_addr(void);
int wifi_disconnect(void);
bool wifi_is_connected(void);

#endif // WIFI_H_
```
